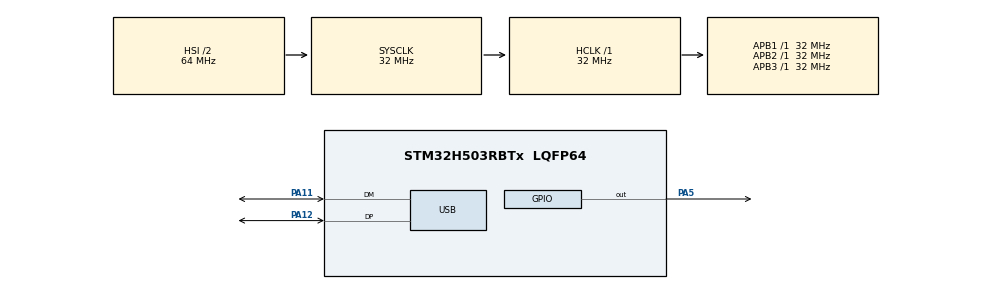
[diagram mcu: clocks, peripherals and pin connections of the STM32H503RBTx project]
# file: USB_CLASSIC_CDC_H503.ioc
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Mcu.Family=STM32H5
Mcu.Name=STM32H503RBTx
Mcu.Package=LQFP64
NVIC.PriorityGroup=NVIC_PRIORITYGROUP_4
NVIC.USB_DRD_FS_IRQn=true\:0\:0\:false\:false\:true\:true\:true\:true
PA11.Mode=Device
PA11.Signal=USB_DM
PA12.Mode=Device
PA12.Signal=USB_DP
PA5.Signal=GPIO_Output
ProjectManager.HeapSize=0x300
ProjectManager.StackSize=0x500
ProjectManager.TargetToolchain=STM32CubeIDE
RCC.ADCFreq_Value=32000000
RCC.AHBFreq_Value=32000000
RCC.APB1Freq_Value=32000000
RCC.APB1TimFreq_Value=32000000
RCC.APB2Freq_Value=32000000
RCC.APB2TimFreq_Value=32000000
RCC.APB3Freq_Value=32000000
RCC.CSI_VALUE=4000000
RCC.CortexFreq_Value=32000000
RCC.EPOD_VALUE=4000000
RCC.HCLKFreq_Value=32000000
RCC.HSE_VALUE=25000000
RCC.HSI48_VALUE=48000000
RCC.HSI_VALUE=64000000
RCC.LSE_VALUE=32768
RCC.LSIRC_VALUE=32000
RCC.SYSCLKFreq_VALUE=32000000
RCC.USBFreq_Value=48000000
RCC.VCOOutputFreq_Value=516000000
USB.VirtualMode=Device_Only
VP_BOOTPATH_VS_BOOTPATH.Mode=BP_Activate
VP_MEMORYMAP_VS_MEMORYMAP.Mode=CurAppReg
VP_PWR_VS_DBSignals.Mode=DisableDeadBatterySignals
VP_PWR_VS_LPOM.Mode=PowerOptimisation
VP_PWR_VS_SECSignals.Mode=Security/Privilege
board=custom

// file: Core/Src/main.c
/* USER CODE BEGIN Header */
/**
 ******************************************************************************
 * @file           : main.c
 * @brief          : Main program body
 ******************************************************************************
 * @attention
 *
 * Copyright (c) 2023 STMicroelectronics.
 * All rights reserved.
 *
 * This software is licensed under terms that can be found in the LICENSE file
 * in the root directory of this software component.
 * If no LICENSE file comes with this software, it is provided AS-IS.
 *
 ******************************************************************************
 */
/* USER CODE END Header */
#include "main.h"

/* USER CODE BEGIN Includes */
#include "usbd_core.h"
#include "usbd_cdc_if.h"
/* USER CODE END Includes */

PCD_HandleTypeDef hpcd_USB_DRD_FS;

/* USER CODE BEGIN PV */
USBD_HandleTypeDef hUsbDeviceFS;
extern USBD_DescriptorsTypeDef Class_Desc;
/* USER CODE END PV */

void SystemClock_Config(void);
static void MX_GPIO_Init(void);
static void MX_MEMORYMAP_Init(void);
static void MX_USB_PCD_Init(void);

int main(void)
{
  /* USER CODE BEGIN 1 */
	uint8_t TxMessageBuffer[] = "MY USB IS WORKING! \r\n";
  /* USER CODE END 1 */

  /* MCU Configuration--------------------------------------------------------*/

  /* Reset of all peripherals, Initializes the Flash interface and the Systick. */
  HAL_Init();

  /* Configure the system clock */
  SystemClock_Config();

  /* Initialize all configured peripherals */
  MX_GPIO_Init();
  MX_MEMORYMAP_Init();
  MX_USB_PCD_Init();
  /* USER CODE BEGIN 2 */
	while(hUsbDeviceFS.pClassData == NULL);
  /* USER CODE END 2 */

  /* Infinite loop */
  /* USER CODE BEGIN WHILE */
	while (1)
	{
		TEMPLATE_Transmit(TxMessageBuffer, sizeof(TxMessageBuffer));
		HAL_Delay(500);
    /* USER CODE END WHILE */

	}
}

void SystemClock_Config(void)
{
  RCC_OscInitTypeDef RCC_OscInitStruct = {0};
  RCC_ClkInitTypeDef RCC_ClkInitStruct = {0};

  /** Configure the main internal regulator output voltage
  */
  __HAL_PWR_VOLTAGESCALING_CONFIG(PWR_REGULATOR_VOLTAGE_SCALE3);

  while(!__HAL_PWR_GET_FLAG(PWR_FLAG_VOSRDY)) {}

  /** Initializes the RCC Oscillators according to the specified parameters
  * in the RCC_OscInitTypeDef structure.
  */
  RCC_OscInitStruct.OscillatorType = RCC_OSCILLATORTYPE_HSI48|RCC_OSCILLATORTYPE_HSI;
  RCC_OscInitStruct.HSIState = RCC_HSI_ON;
  RCC_OscInitStruct.HSIDiv = RCC_HSI_DIV2;
  RCC_OscInitStruct.HSICalibrationValue = RCC_HSICALIBRATION_DEFAULT;
  RCC_OscInitStruct.HSI48State = RCC_HSI48_ON;
  RCC_OscInitStruct.PLL.PLLState = RCC_PLL_NONE;
  if (HAL_RCC_OscConfig(&RCC_OscInitStruct) != HAL_OK)
  {
    Error_Handler();
  }

  /** Initializes the CPU, AHB and APB buses clocks
  */
  RCC_ClkInitStruct.ClockType = RCC_CLOCKTYPE_HCLK|RCC_CLOCKTYPE_SYSCLK
                              |RCC_CLOCKTYPE_PCLK1|RCC_CLOCKTYPE_PCLK2
                              |RCC_CLOCKTYPE_PCLK3;
  RCC_ClkInitStruct.SYSCLKSource = RCC_SYSCLKSOURCE_HSI;
  RCC_ClkInitStruct.AHBCLKDivider = RCC_SYSCLK_DIV1;
  RCC_ClkInitStruct.APB1CLKDivider = RCC_HCLK_DIV1;
  RCC_ClkInitStruct.APB2CLKDivider = RCC_HCLK_DIV1;
  RCC_ClkInitStruct.APB3CLKDivider = RCC_HCLK_DIV1;

  if (HAL_RCC_ClockConfig(&RCC_ClkInitStruct, FLASH_LATENCY_1) != HAL_OK)
  {
    Error_Handler();
  }
}

static void MX_MEMORYMAP_Init(void)
{

}

static void MX_USB_PCD_Init(void)
{

  /* USER CODE BEGIN USB_Init 0 */
	hpcd_USB_DRD_FS.pData = &hUsbDeviceFS;
  /* USER CODE END USB_Init 0 */

  hpcd_USB_DRD_FS.Instance = USB_DRD_FS;
  hpcd_USB_DRD_FS.Init.dev_endpoints = 8;
  hpcd_USB_DRD_FS.Init.speed = USBD_FS_SPEED;
  hpcd_USB_DRD_FS.Init.phy_itface = PCD_PHY_EMBEDDED;
  hpcd_USB_DRD_FS.Init.Sof_enable = DISABLE;
  hpcd_USB_DRD_FS.Init.low_power_enable = DISABLE;
  hpcd_USB_DRD_FS.Init.lpm_enable = DISABLE;
  hpcd_USB_DRD_FS.Init.battery_charging_enable = DISABLE;
  hpcd_USB_DRD_FS.Init.vbus_sensing_enable = DISABLE;
  hpcd_USB_DRD_FS.Init.bulk_doublebuffer_enable = DISABLE;
  hpcd_USB_DRD_FS.Init.iso_singlebuffer_enable = DISABLE;
  if (HAL_PCD_Init(&hpcd_USB_DRD_FS) != HAL_OK)
  {
    Error_Handler();
  }
  /* USER CODE BEGIN USB_Init 2 */
	if(USBD_Init(&hUsbDeviceFS, &Class_Desc, 0) != USBD_OK)
		Error_Handler();

	if (USBD_RegisterClass(&hUsbDeviceFS, &USBD_CDC) != USBD_OK)
		Error_Handler();

	if(USBD_CDC_RegisterInterface(&hUsbDeviceFS, &USBD_CDC_Template_fops) != USBD_OK)
		Error_Handler();

	if(USBD_Start(&hUsbDeviceFS) != USBD_OK)
		Error_Handler();
  /* USER CODE END USB_Init 2 */

}

static void MX_GPIO_Init(void)
{
  GPIO_InitTypeDef GPIO_InitStruct = {0};

  /* GPIO Ports Clock Enable */
  __HAL_RCC_GPIOA_CLK_ENABLE();

  /*Configure GPIO pin Output Level */
  HAL_GPIO_WritePin(GPIOA, GPIO_PIN_5, GPIO_PIN_RESET);

  /*Configure GPIO pin : PA5 */
  GPIO_InitStruct.Pin = GPIO_PIN_5;
  GPIO_InitStruct.Mode = GPIO_MODE_OUTPUT_PP;
  GPIO_InitStruct.Pull = GPIO_NOPULL;
  GPIO_InitStruct.Speed = GPIO_SPEED_FREQ_LOW;
  HAL_GPIO_Init(GPIOA, &GPIO_InitStruct);

}

void Error_Handler(void)
{
	__disable_irq();
	while (1)
	{
	}
}
